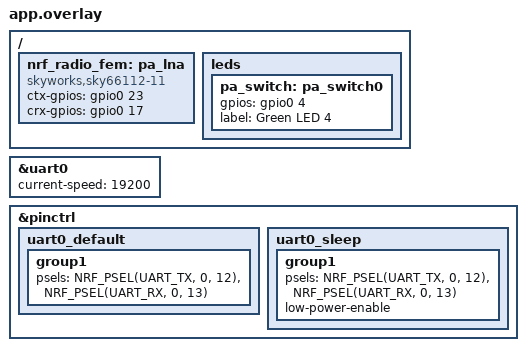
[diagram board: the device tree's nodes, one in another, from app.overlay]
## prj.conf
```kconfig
#
# Copyright (c) 2020 Nordic Semiconductor
#
# SPDX-License-Identifier: LicenseRef-Nordic-5-Clause
#

# Configure assertions
CONFIG_ASSERT=y
CONFIG_ASSERT_NO_COND_INFO=y
CONFIG_ASSERT_NO_MSG_INFO=y

CONFIG_HW_STACK_PROTECTION=y

# Use RTT console
CONFIG_USE_SEGGER_RTT=y
CONFIG_RTT_CONSOLE=y
CONFIG_UART_CONSOLE=n

# Use necessary peripherals
CONFIG_NRFX_TIMER0=y
CONFIG_NRFX_TIMER1=y
CONFIG_NRFX_TIMER2=y

### reset pin as gpio
CONFIG_GPIO_AS_PINRESET=n

CONFIG_GPIO=y
```

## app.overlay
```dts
&uart0 {
	status = "okay";
	current-speed = <19200>;
};

&pinctrl {
    uart0_default: uart0_default {
        group1 {
            psels = <NRF_PSEL(UART_TX, 0, 12)>,
                <NRF_PSEL(UART_RX, 0, 13)>;
        };
    };

    uart0_sleep: uart0_sleep {
        group1 {
            psels = <NRF_PSEL(UART_TX, 0, 12)>,
                <NRF_PSEL(UART_RX, 0, 13)>;
            low-power-enable;
        };
    };
};

/ {
    nrf_radio_fem: pa_lna {
        compatible = "skyworks,sky66112-11", "generic-fem-two-ctrl-pins";
        ctx-gpios = <&gpio0 23 GPIO_ACTIVE_HIGH>;
        crx-gpios = <&gpio0 17 GPIO_ACTIVE_HIGH>;
    };
};

/ {
    /delete-node/ aliases;
};
/ {
    leds {
        /delete-node/ led_0;
        /delete-node/ led_1;
        /delete-node/ led_2;
        /delete-node/ led_3;
        pa_switch: pa_switch0 {
            gpios = <&gpio0 4 GPIO_ACTIVE_HIGH>;
            label = "Green LED 4";
        };
    };
};
```

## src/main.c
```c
/*
 * Copyright (c) 2020 Nordic Semiconductor ASA
 *
 * SPDX-License-Identifier: LicenseRef-Nordic-5-Clause
 */

#include <errno.h>
#include <zephyr/drivers/uart.h>
#include <zephyr/kernel.h>
#include <zephyr/drivers/gpio.h>

#include "dtm.h"
#define PA_POWER_NODE DT_NODELABEL(pa_switch)

void main(void)
{
	int err;
	const struct device *uart = DEVICE_DT_GET(DT_NODELABEL(uart0));
    static const struct gpio_dt_spec pa_power = GPIO_DT_SPEC_GET(PA_POWER_NODE, gpios);
	bool is_msb_read = false;
	uint8_t rx_byte;
	uint16_t dtm_cmd;
	uint16_t dtm_evt;
	int64_t msb_time;

	printk("Starting Direct Test Mode example\n");

    err = gpio_pin_configure_dt(&pa_power, GPIO_OUTPUT_ACTIVE);
	if (err < 0) {
		printk("PA Power Pin not ready\n");
	}
    gpio_pin_set_dt(&pa_power, 1);

	if (!device_is_ready(uart)) {
		printk("UART device not ready\n");
	}

	err = dtm_init();
	if (err) {
		printk("Error during DTM initialization: %d\n", err);
	}

	for (;;) {
		dtm_wait();

		err = uart_poll_in(uart, &rx_byte);
		if (err) {
			if (err != -1) {
				printk("UART polling error: %d\n", err);
			}

			/* Nothing read from the UART. */
			continue;
		}

		if (!is_msb_read) {
			/* This is first byte of two-byte command. */
			is_msb_read = true;
			dtm_cmd = rx_byte << 8;
			msb_time = k_uptime_get();

			/* Go back and wait for 2nd byte of command word. */
			continue;
		}

		/* This is the second byte read; combine it with the first and
		 * process command.
		 */
		if ((k_uptime_get() - msb_time) >
		    DTM_UART_SECOND_BYTE_MAX_DELAY) {
			/* More than ~5mS after msb: Drop old byte, take the
			 * new byte as MSB. The variable is_msb_read will
			 * remain true.
			 */
			dtm_cmd = rx_byte << 8;
			msb_time = k_uptime_get();
			/* Go back and wait for 2nd byte of command word. */
			continue;
		}

		/* 2-byte UART command received. */
		is_msb_read = false;
		dtm_cmd |= rx_byte;

		printk("Sending 0x%04X DTM command\n", dtm_cmd);

		if (dtm_cmd_put(dtm_cmd) != DTM_SUCCESS) {
			/* Extended error handling may be put here.
			 * Default behavior is to return the event on the UART;
			 * the event report will reflect any lack of success.
			 */
		}

		/* Retrieve result of the operation. This implementation will
		 * busy-loop for the duration of the byte transmissions on the
		 * UART.
		 */
		if (dtm_event_get(&dtm_evt)) {
			printk("Received 0x%04X DTM event\n", dtm_evt);

			/* Report command status on the UART. */

			/* Transmit MSB of the result. */
			uart_poll_out(uart, (dtm_evt >> 8) & 0xFF);

			/* Transmit LSB of the result. */
			uart_poll_out(uart, dtm_evt & 0xFF);
		}
	}
}
```
